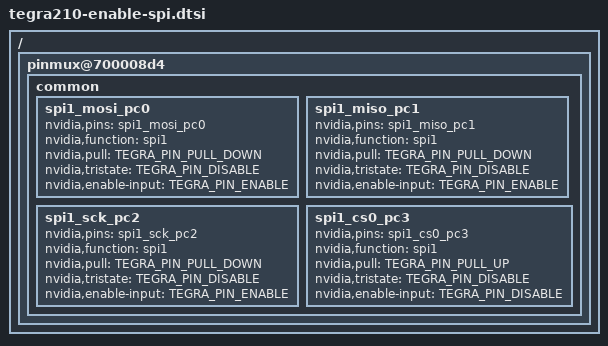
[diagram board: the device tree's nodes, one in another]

#include "porg-platforms/tegra210-porg-pinmux-p3448-0002-b00.dtsi"
#include "porg-platforms/tegra210-porg-gpio-p3448-0002-b00.dtsi"

/ {
	/* Enable SPI lane */
	pinmux@700008d4 {
		common {
			spi1_mosi_pc0 {
				nvidia,pins = "spi1_mosi_pc0";
				nvidia,function = "spi1";
				nvidia,pull = <TEGRA_PIN_PULL_DOWN>;
				nvidia,tristate = <TEGRA_PIN_DISABLE>;
				nvidia,enable-input = <TEGRA_PIN_ENABLE>;
			};

			spi1_miso_pc1 {
				nvidia,pins = "spi1_miso_pc1";
				nvidia,function = "spi1";
				nvidia,pull = <TEGRA_PIN_PULL_DOWN>;
				nvidia,tristate = <TEGRA_PIN_DISABLE>;
				nvidia,enable-input = <TEGRA_PIN_ENABLE>;
			};

			spi1_sck_pc2 {
				nvidia,pins = "spi1_sck_pc2";
				nvidia,function = "spi1";
				nvidia,pull = <TEGRA_PIN_PULL_DOWN>;
				nvidia,tristate = <TEGRA_PIN_DISABLE>;
				nvidia,enable-input = <TEGRA_PIN_ENABLE>;
			};

			spi1_cs0_pc3 {
				nvidia,pins = "spi1_cs0_pc3";
				nvidia,function = "spi1";
				nvidia,pull = <TEGRA_PIN_PULL_UP>;
				nvidia,tristate = <TEGRA_PIN_DISABLE>;
				nvidia,enable-input = <TEGRA_PIN_DISABLE>;
			};
		};
	};

};
